# STM32H7B3ZIT6Q register map
File version: 1.0
Registers are 32-bit, access not given, reset 0x0 unless marked. A register's access mark holds for its fields unless they carry their own. Offsets are from the block's base; [hi:lo] are bit positions; 'fields as' and 'values as' point back to an identical list.

## DFSDM1
Base 0x40017800
Same registers: DFSDM2 0x58006C00
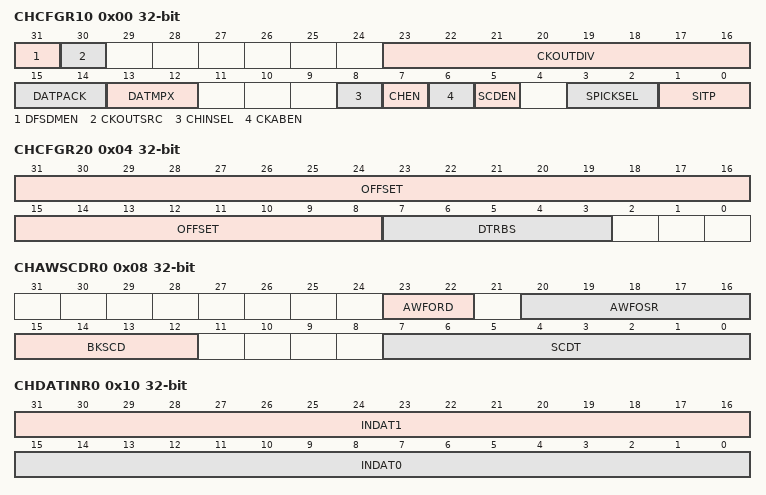
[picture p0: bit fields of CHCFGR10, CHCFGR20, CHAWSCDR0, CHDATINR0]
0x00 CHCFGR10
  [31] DFSDMEN, [30] CKOUTSRC, [23:16] CKOUTDIV, [15:14] DATPACK, [13:12] DATMPX, [8] CHINSEL, [7] CHEN, [6] CKABEN, [5] SCDEN, [3:2] SPICKSEL, [1:0] SITP
0x04 CHCFGR20
  [31:8] OFFSET, [7:3] DTRBS
0x08 CHAWSCDR0
  [23:22] AWFORD, [20:16] AWFOSR, [15:12] BKSCD, [7:0] SCDT
0x0C CHWDATAR0
0x10 CHDATINR0
  [31:16] INDAT1, [15:0] INDAT0
0x14 CHDLYR0
  [5:0] PLSSKP
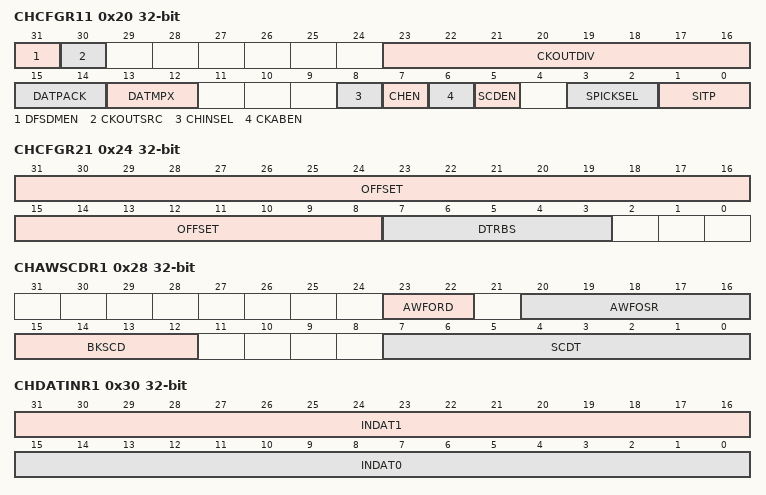
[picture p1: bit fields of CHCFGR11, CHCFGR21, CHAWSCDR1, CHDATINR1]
0x20 CHCFGR11
  fields as CHCFGR10
0x24 CHCFGR21
  [31:8] OFFSET, [7:3] DTRBS
0x28 CHAWSCDR1
  [23:22] AWFORD, [20:16] AWFOSR, [15:12] BKSCD, [7:0] SCDT
0x2C CHWDATAR1
0x30 CHDATINR1
  [31:16] INDAT1, [15:0] INDAT0
0x34 CHDLYR1
  [5:0] PLSSKP
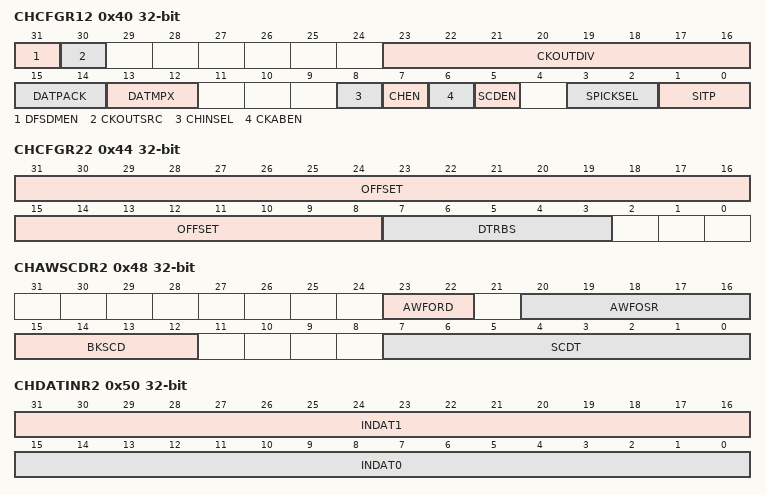
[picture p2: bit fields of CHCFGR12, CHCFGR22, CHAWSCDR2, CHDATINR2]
0x40 CHCFGR12
  fields as CHCFGR10
0x44 CHCFGR22
  [31:8] OFFSET, [7:3] DTRBS
0x48 CHAWSCDR2
  [23:22] AWFORD, [20:16] AWFOSR, [15:12] BKSCD, [7:0] SCDT
0x4C CHWDATAR2
0x50 CHDATINR2
  [31:16] INDAT1, [15:0] INDAT0
0x54 CHDLYR2
  [5:0] PLSSKP
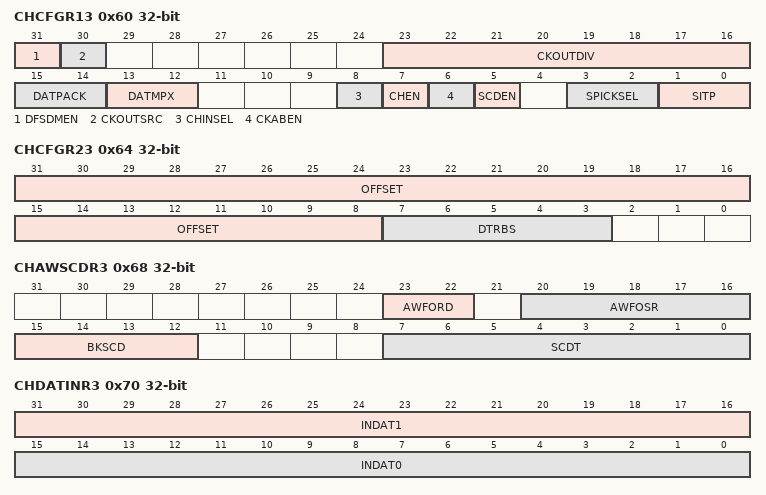
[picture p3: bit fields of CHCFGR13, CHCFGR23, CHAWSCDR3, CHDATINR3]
0x60 CHCFGR13
  fields as CHCFGR10
0x64 CHCFGR23
  [31:8] OFFSET, [7:3] DTRBS
0x68 CHAWSCDR3
  [23:22] AWFORD, [20:16] AWFOSR, [15:12] BKSCD, [7:0] SCDT
0x6C CHWDATAR3
0x70 CHDATINR3
  [31:16] INDAT1, [15:0] INDAT0
0x74 CHDLYR3
  [5:0] PLSSKP
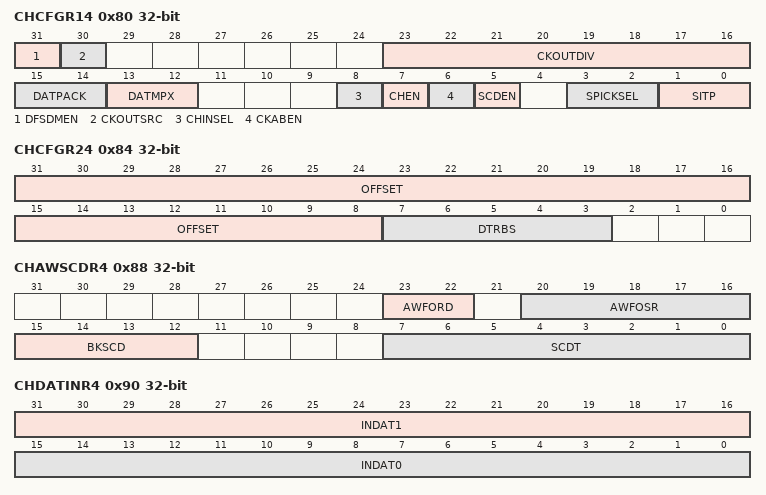
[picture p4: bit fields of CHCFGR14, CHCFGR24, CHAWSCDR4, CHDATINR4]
0x80 CHCFGR14
  fields as CHCFGR10
0x84 CHCFGR24
  [31:8] OFFSET, [7:3] DTRBS
0x88 CHAWSCDR4
  [23:22] AWFORD, [20:16] AWFOSR, [15:12] BKSCD, [7:0] SCDT
0x8C CHWDATAR4
0x90 CHDATINR4
  [31:16] INDAT1, [15:0] INDAT0
0x94 CHDLYR4
  [5:0] PLSSKP
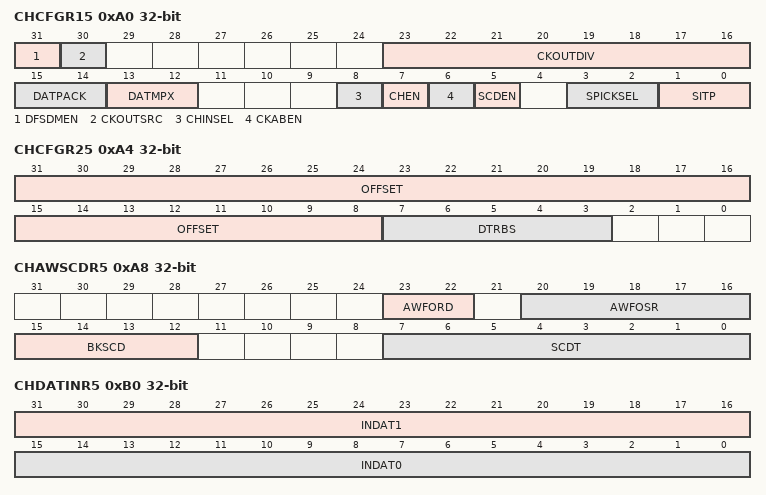
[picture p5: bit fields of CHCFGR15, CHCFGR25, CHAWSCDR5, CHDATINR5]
0xA0 CHCFGR15
  fields as CHCFGR10
0xA4 CHCFGR25
  [31:8] OFFSET, [7:3] DTRBS
0xA8 CHAWSCDR5
  [23:22] AWFORD, [20:16] AWFOSR, [15:12] BKSCD, [7:0] SCDT
0xAC CHWDATAR5
0xB0 CHDATINR5
  [31:16] INDAT1, [15:0] INDAT0
0xB4 CHDLYR5
  [5:0] PLSSKP
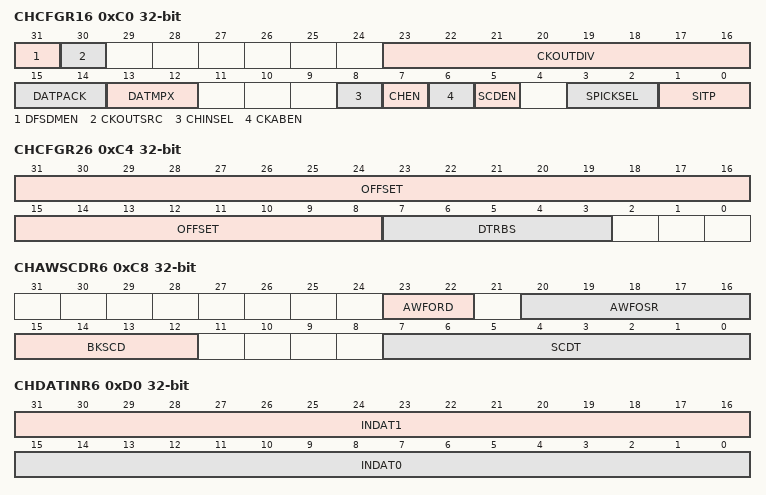
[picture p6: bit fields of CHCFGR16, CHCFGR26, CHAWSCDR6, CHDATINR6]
0xC0 CHCFGR16
  fields as CHCFGR10
0xC4 CHCFGR26
  [31:8] OFFSET, [7:3] DTRBS
0xC8 CHAWSCDR6
  [23:22] AWFORD, [20:16] AWFOSR, [15:12] BKSCD, [7:0] SCDT
0xCC CHWDATAR6
0xD0 CHDATINR6
  [31:16] INDAT1, [15:0] INDAT0
0xD4 CHDLYR6
  [5:0] PLSSKP
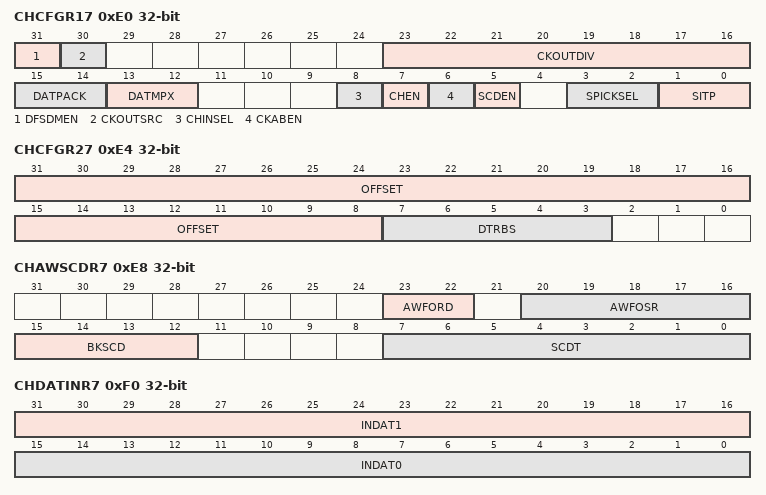
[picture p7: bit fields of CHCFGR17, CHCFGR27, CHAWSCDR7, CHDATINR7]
0xE0 CHCFGR17
  fields as CHCFGR10
0xE4 CHCFGR27
  [31:8] OFFSET, [7:3] DTRBS
0xE8 CHAWSCDR7
  [23:22] AWFORD, [20:16] AWFOSR, [15:12] BKSCD, [7:0] SCDT
0xEC CHWDATAR7
0xF0 CHDATINR7
  [31:16] INDAT1, [15:0] INDAT0
0xF4 CHDLYR7
  [5:0] PLSSKP
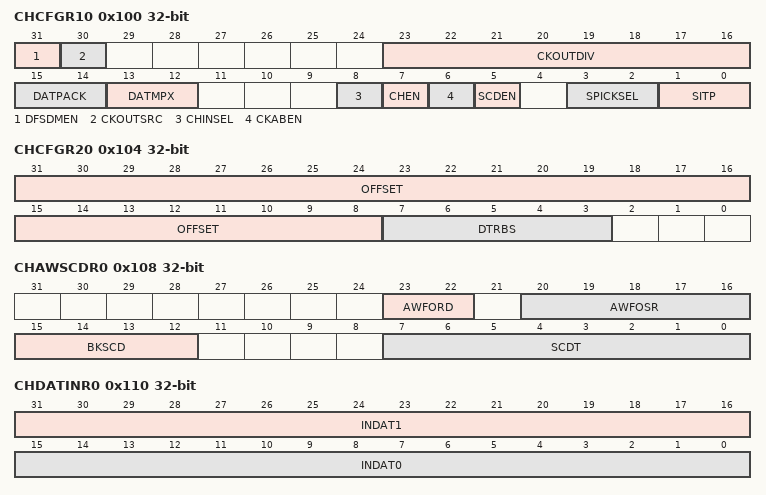
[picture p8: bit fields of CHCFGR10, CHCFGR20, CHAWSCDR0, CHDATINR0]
0x100 CHCFGR10
  fields as CHCFGR10
0x104 CHCFGR20
  [31:8] OFFSET, [7:3] DTRBS
0x108 CHAWSCDR0
  [23:22] AWFORD, [20:16] AWFOSR, [15:12] BKSCD, [7:0] SCDT
0x10C CHWDATAR0
0x110 CHDATINR0
  [31:16] INDAT1, [15:0] INDAT0
0x114 CHDLYR0
  [5:0] PLSSKP
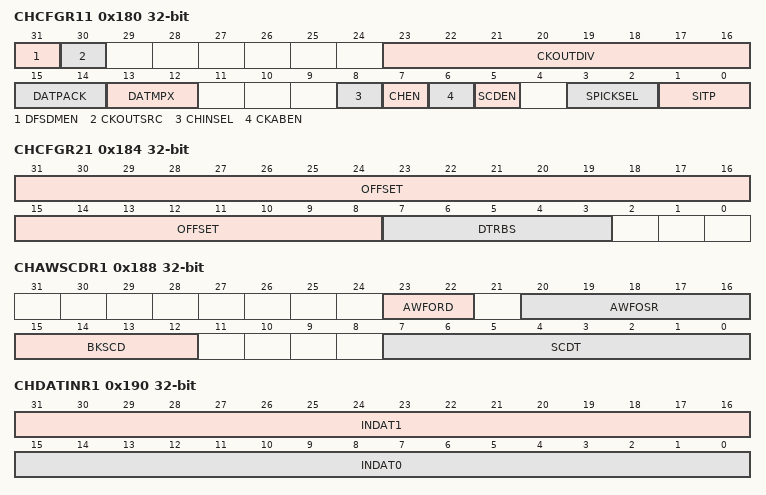
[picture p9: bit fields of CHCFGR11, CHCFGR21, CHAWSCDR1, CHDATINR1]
0x180 CHCFGR11
  fields as CHCFGR10
0x184 CHCFGR21
  [31:8] OFFSET, [7:3] DTRBS
0x188 CHAWSCDR1
  [23:22] AWFORD, [20:16] AWFOSR, [15:12] BKSCD, [7:0] SCDT
0x18C CHWDATAR1
0x190 CHDATINR1
  [31:16] INDAT1, [15:0] INDAT0
0x194 CHDLYR1
  [5:0] PLSSKP
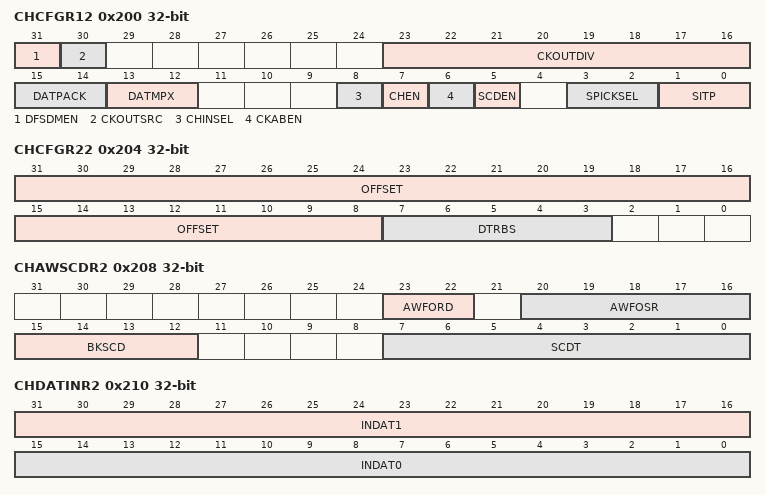
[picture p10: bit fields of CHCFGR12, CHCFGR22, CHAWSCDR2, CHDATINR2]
0x200 CHCFGR12
  fields as CHCFGR10
0x204 CHCFGR22
  [31:8] OFFSET, [7:3] DTRBS
0x208 CHAWSCDR2
  [23:22] AWFORD, [20:16] AWFOSR, [15:12] BKSCD, [7:0] SCDT
0x20C CHWDATAR2
0x210 CHDATINR2
  [31:16] INDAT1, [15:0] INDAT0
0x214 CHDLYR2
  [5:0] PLSSKP
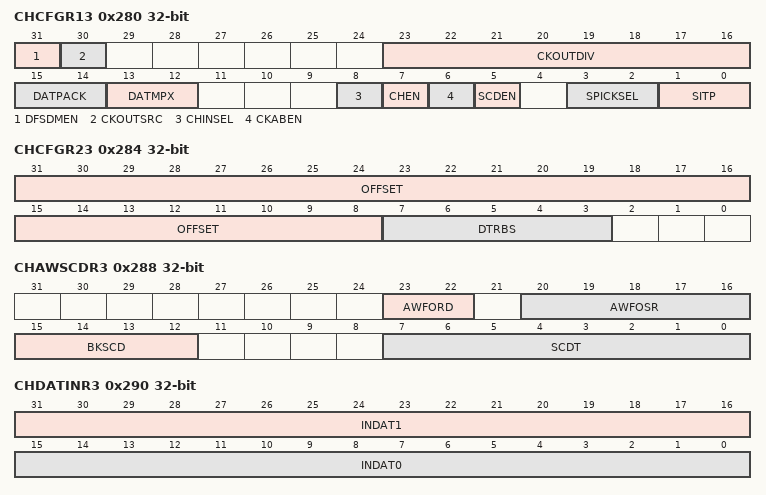
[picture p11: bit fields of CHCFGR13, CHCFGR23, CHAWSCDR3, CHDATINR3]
0x280 CHCFGR13
  fields as CHCFGR10
0x284 CHCFGR23
  [31:8] OFFSET, [7:3] DTRBS
0x288 CHAWSCDR3
  [23:22] AWFORD, [20:16] AWFOSR, [15:12] BKSCD, [7:0] SCDT
0x28C CHWDATAR3
0x290 CHDATINR3
  [31:16] INDAT1, [15:0] INDAT0
0x294 CHDLYR3
  [5:0] PLSSKP
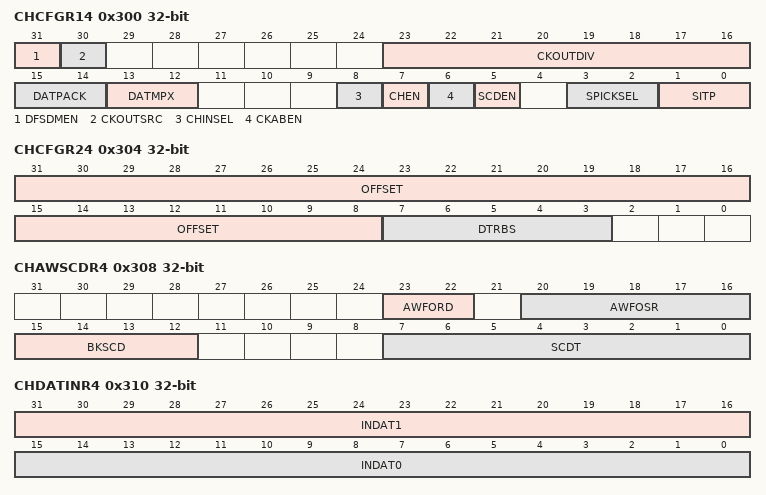
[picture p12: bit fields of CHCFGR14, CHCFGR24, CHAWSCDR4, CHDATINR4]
0x300 CHCFGR14
  fields as CHCFGR10
0x304 CHCFGR24
  [31:8] OFFSET, [7:3] DTRBS
0x308 CHAWSCDR4
  [23:22] AWFORD, [20:16] AWFOSR, [15:12] BKSCD, [7:0] SCDT
0x30C CHWDATAR4
0x310 CHDATINR4
  [31:16] INDAT1, [15:0] INDAT0
0x314 CHDLYR4
  [5:0] PLSSKP
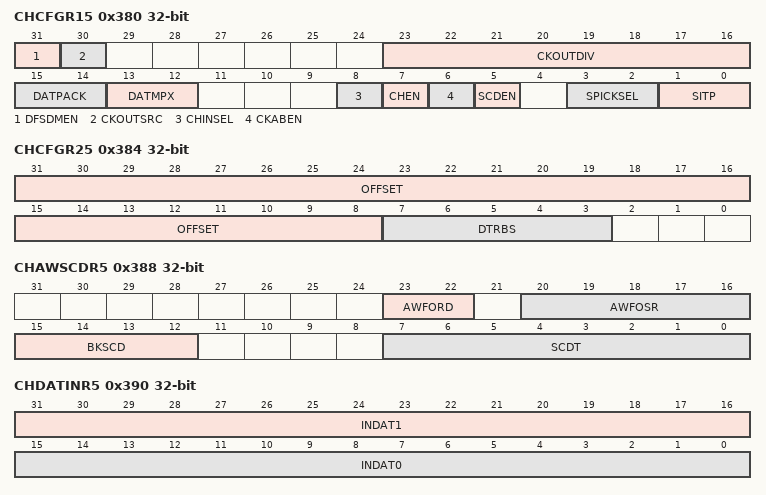
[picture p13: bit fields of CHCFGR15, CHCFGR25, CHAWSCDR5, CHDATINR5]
0x380 CHCFGR15
  fields as CHCFGR10
0x384 CHCFGR25
  [31:8] OFFSET, [7:3] DTRBS
0x388 CHAWSCDR5
  [23:22] AWFORD, [20:16] AWFOSR, [15:12] BKSCD, [7:0] SCDT
0x38C CHWDATAR5
0x390 CHDATINR5
  [31:16] INDAT1, [15:0] INDAT0
0x394 CHDLYR5
  [5:0] PLSSKP
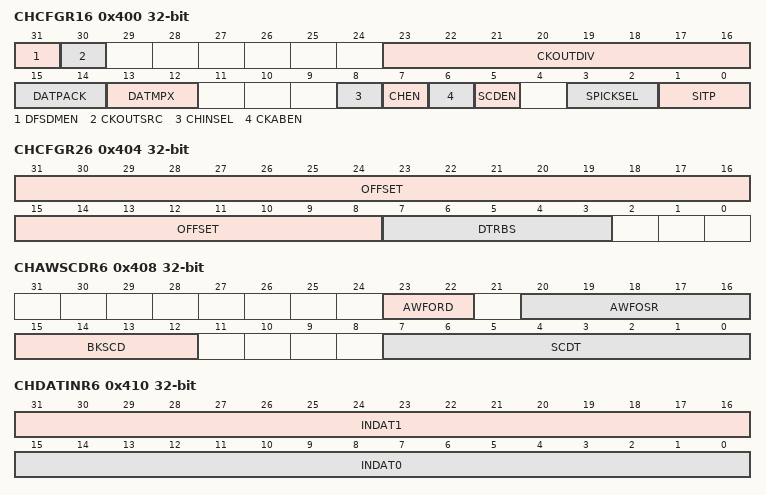
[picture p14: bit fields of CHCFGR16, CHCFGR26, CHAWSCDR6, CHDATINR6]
0x400 CHCFGR16
  fields as CHCFGR10
0x404 CHCFGR26
  [31:8] OFFSET, [7:3] DTRBS
0x408 CHAWSCDR6
  [23:22] AWFORD, [20:16] AWFOSR, [15:12] BKSCD, [7:0] SCDT
0x40C CHWDATAR6
0x410 CHDATINR6
  [31:16] INDAT1, [15:0] INDAT0
0x414 CHDLYR6
  [5:0] PLSSKP
0x480 CHCFGR17
  fields as CHCFGR10
0x484 CHCFGR27
  [31:8] OFFSET, [7:3] DTRBS
0x488 CHAWSCDR7
  [23:22] AWFORD, [20:16] AWFOSR, [15:12] BKSCD, [7:0] SCDT
0x48C CHWDATAR7
0x490 CHDATINR7
  [31:16] INDAT1, [15:0] INDAT0
0x494 CHDLYR7
  [5:0] PLSSKP
